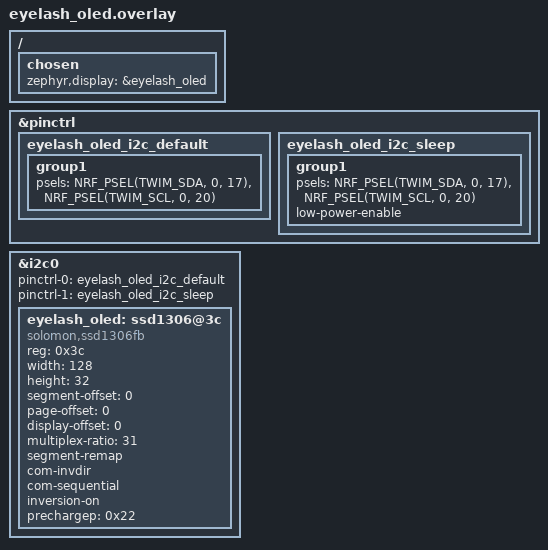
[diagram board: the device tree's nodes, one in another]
/*
 * OLED wiring from the vendor's zmk-corne-oled shield.
 * Copyright (c) 2021 Darryl deHaan
 * SPDX-License-Identifier: MIT
 */

/ {
    chosen {
        zephyr,display = &eyelash_oled;
    };
};

&pinctrl {
    eyelash_oled_i2c_default: eyelash_oled_i2c_default {
        group1 {
            psels = <NRF_PSEL(TWIM_SDA, 0, 17)>,
                    <NRF_PSEL(TWIM_SCL, 0, 20)>;
        };
    };

    eyelash_oled_i2c_sleep: eyelash_oled_i2c_sleep {
        group1 {
            psels = <NRF_PSEL(TWIM_SDA, 0, 17)>,
                    <NRF_PSEL(TWIM_SCL, 0, 20)>;
            low-power-enable;
        };
    };
};

&i2c0 {
    status = "okay";
    pinctrl-0 = <&eyelash_oled_i2c_default>;
    pinctrl-1 = <&eyelash_oled_i2c_sleep>;
    pinctrl-names = "default", "sleep";

    eyelash_oled: ssd1306@3c {
        compatible = "solomon,ssd1306fb";
        reg = <0x3c>;
        width = <128>;
        height = <32>;
        segment-offset = <0>;
        page-offset = <0>;
        display-offset = <0>;
        multiplex-ratio = <31>;
        segment-remap;
        com-invdir;
        com-sequential;
        inversion-on;
        prechargep = <0x22>;
    };
};
